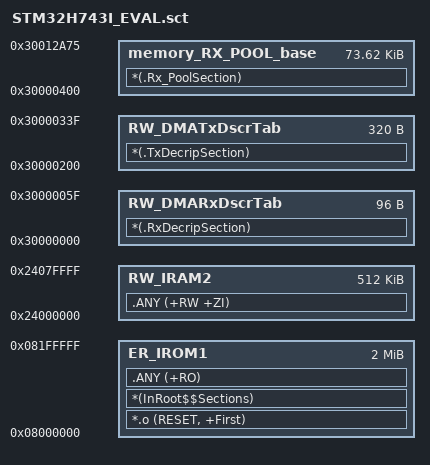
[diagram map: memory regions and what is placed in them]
; *************************************************************
; *** Scatter-Loading Description File generated by uVision ***
; *************************************************************

LR_IROM1 0x08000000 0x00200000  {    ; load region size_region
  ER_IROM1 0x08000000 0x00200000  {  ; load address = execution address
   *.o (RESET, +First)
   *(InRoot$$Sections)
   .ANY (+RO)
  }
  RW_IRAM2 0x24000000 0x00080000  {  ; RW data
   .ANY (+RW +ZI)
  }
  RW_DMARxDscrTab 0x30000000 0x60 {
  *(.RxDecripSection)
  }
  RW_DMATxDscrTab 0x30000200 0x140 {
  *(.TxDecripSection)
  }
  memory_RX_POOL_base 0x30000400 0x12676 {
  *(.Rx_PoolSection)
  }

}




